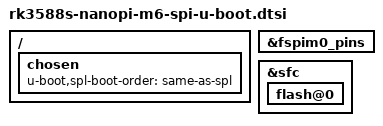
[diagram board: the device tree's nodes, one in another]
#include "rk3588s-u-boot.dtsi"

/ {
	chosen {
		u-boot,spl-boot-order = "same-as-spl", &sdmmc;
	};
};

&fspim0_pins {
	bootph-pre-ram;
	bootph-some-ram;
};

&sfc {
	flash@0 {
		bootph-pre-ram;
		bootph-some-ram;
	};
};
